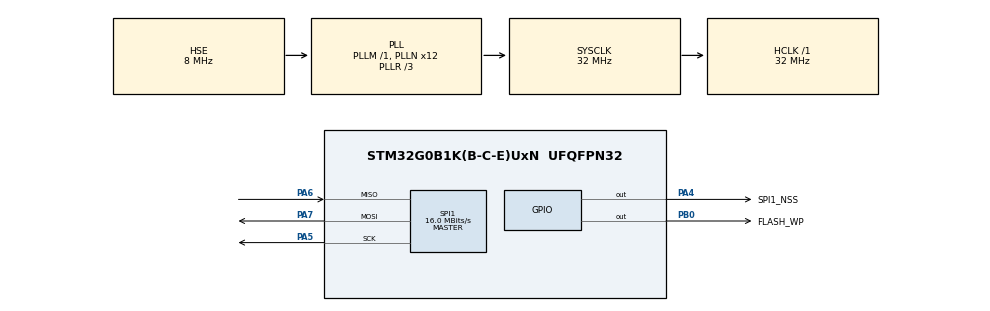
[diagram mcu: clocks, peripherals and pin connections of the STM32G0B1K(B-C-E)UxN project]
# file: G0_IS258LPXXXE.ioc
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Mcu.Family=STM32G0
Mcu.Name=STM32G0B1K(B-C-E)UxN
Mcu.Package=UFQFPN32
PA13.Mode=Serial_Wire
PA13.Signal=SYS_SWDIO
PA14-BOOT0.Mode=Serial_Wire
PA14-BOOT0.Signal=SYS_SWCLK
PA4.GPIO_Label=SPI1_NSS
PA4.Signal=GPIO_Output
PA5.Mode=Full_Duplex_Master
PA5.Signal=SPI1_SCK
PA6.Mode=Full_Duplex_Master
PA6.Signal=SPI1_MISO
PA7.Mode=Full_Duplex_Master
PA7.Signal=SPI1_MOSI
PB0.GPIO_Label=FLASH_WP
PB0.Signal=GPIO_Output
PC14-OSC32_IN\ (PC14).Mode=HSE-External-Clock-Source
PC14-OSC32_IN\ (PC14).Signal=RCC_OSC_IN
ProjectManager.HeapSize=0x200
ProjectManager.StackSize=0x400
ProjectManager.TargetToolchain=STM32CubeIDE
RCC.ADCFreq_Value=32000000
RCC.AHBFreq_Value=32000000
RCC.CortexFreq_Value=32000000
RCC.EXTERNAL_CLOCK_VALUE=48000
RCC.HCLKFreq_Value=32000000
RCC.HSE_VALUE=8000000
RCC.HSI48_VALUE=48000000
RCC.HSI_VALUE=16000000
RCC.LSE_VALUE=32768
RCC.PLLN=12
RCC.PLLR=RCC_PLLR_DIV3
RCC.PLLSourceVirtual=RCC_PLLSOURCE_HSE
RCC.SYSCLKFreq_VALUE=32000000
RCC.SYSCLKSource=RCC_SYSCLKSOURCE_PLLCLK
RCC.USBFreq_Value=48000000
RCC.VCOOutputFreq_Value=96000000
SPI1.CalculateBaudRate=16.0 MBits/s
SPI1.DataSize=SPI_DATASIZE_8BIT
SPI1.Direction=SPI_DIRECTION_2LINES
SPI1.Mode=SPI_MODE_MASTER
SPI1.VirtualType=VM_MASTER
VP_SYS_VS_DBSignals.Mode=DisableDeadBatterySignals
board=custom

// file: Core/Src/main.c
/* USER CODE BEGIN Header */
/**
  ******************************************************************************
  * @file           : main.c
  * @brief          : Main program body
  ******************************************************************************
  * @attention
  *
  * Copyright (c) 2025 STMicroelectronics.
  * All rights reserved.
  *
  * This software is licensed under terms that can be found in the LICENSE file
  * in the root directory of this software component.
  * If no LICENSE file comes with this software, it is provided AS-IS.
  *
  ******************************************************************************
  */
/* USER CODE END Header */
#include "main.h"
#include "spi.h"
#include "gpio.h"

/* USER CODE BEGIN Includes */

#include "is25lp040e.h"

/* USER CODE END Includes */

/* USER CODE BEGIN PV */

// IS25LP040E Flash Handle
sIS25LP_Handle_t flash_handle;

/* USER CODE END PV */

void SystemClock_Config(void);

int main(void)
{

  /* MCU Configuration--------------------------------------------------------*/

  /* Reset of all peripherals, Initializes the Flash interface and the Systick. */
  HAL_Init();

  /* Configure the system clock */
  SystemClock_Config();

  /* Initialize all configured peripherals */
  MX_GPIO_Init();
  MX_SPI1_Init();
  /* USER CODE BEGIN 2 */

  // Configure Flash Handle
  flash_handle.spi_handle = &hspi1;
  flash_handle.cs_gpio.port = SPI1_NSS_GPIO_Port;
  flash_handle.cs_gpio.pin = SPI1_NSS_Pin;
  flash_handle.wp_gpio.port = FLASH_WP_GPIO_Port;
  flash_handle.wp_gpio.pin = FLASH_WP_Pin;
  flash_handle.initialized = false;

  // Initialize IS25LP040E SPI Flash
  if( IS25LP_OK == IS25LP_Init( &flash_handle ))
  {
      // Flash initialized successfully
      flash_handle.initialized = true;
  }
  else
  {
      // Flash initialization failed
      Error_Handler();
  }

  /* USER CODE END 2 */

  /* Infinite loop */
  while (1)
  {

  }
}

void SystemClock_Config(void)
{
  RCC_OscInitTypeDef RCC_OscInitStruct = {0};
  RCC_ClkInitTypeDef RCC_ClkInitStruct = {0};

  /** Configure the main internal regulator output voltage
  */
  HAL_PWREx_ControlVoltageScaling(PWR_REGULATOR_VOLTAGE_SCALE1);

  /** Initializes the RCC Oscillators according to the specified parameters
  * in the RCC_OscInitTypeDef structure.
  */
  RCC_OscInitStruct.OscillatorType = RCC_OSCILLATORTYPE_HSE;
  RCC_OscInitStruct.HSEState = RCC_HSE_BYPASS;
  RCC_OscInitStruct.PLL.PLLState = RCC_PLL_ON;
  RCC_OscInitStruct.PLL.PLLSource = RCC_PLLSOURCE_HSE;
  RCC_OscInitStruct.PLL.PLLM = RCC_PLLM_DIV1;
  RCC_OscInitStruct.PLL.PLLN = 12;
  RCC_OscInitStruct.PLL.PLLP = RCC_PLLP_DIV2;
  RCC_OscInitStruct.PLL.PLLQ = RCC_PLLQ_DIV2;
  RCC_OscInitStruct.PLL.PLLR = RCC_PLLR_DIV3;
  if (HAL_RCC_OscConfig(&RCC_OscInitStruct) != HAL_OK)
  {
    Error_Handler();
  }

  /** Initializes the CPU, AHB and APB buses clocks
  */
  RCC_ClkInitStruct.ClockType = RCC_CLOCKTYPE_HCLK|RCC_CLOCKTYPE_SYSCLK
                              |RCC_CLOCKTYPE_PCLK1;
  RCC_ClkInitStruct.SYSCLKSource = RCC_SYSCLKSOURCE_PLLCLK;
  RCC_ClkInitStruct.AHBCLKDivider = RCC_SYSCLK_DIV1;
  RCC_ClkInitStruct.APB1CLKDivider = RCC_HCLK_DIV1;

  if (HAL_RCC_ClockConfig(&RCC_ClkInitStruct, FLASH_LATENCY_1) != HAL_OK)
  {
    Error_Handler();
  }
}

void Error_Handler(void)
{
  __disable_irq();
  while (1)
  {
  }
}
